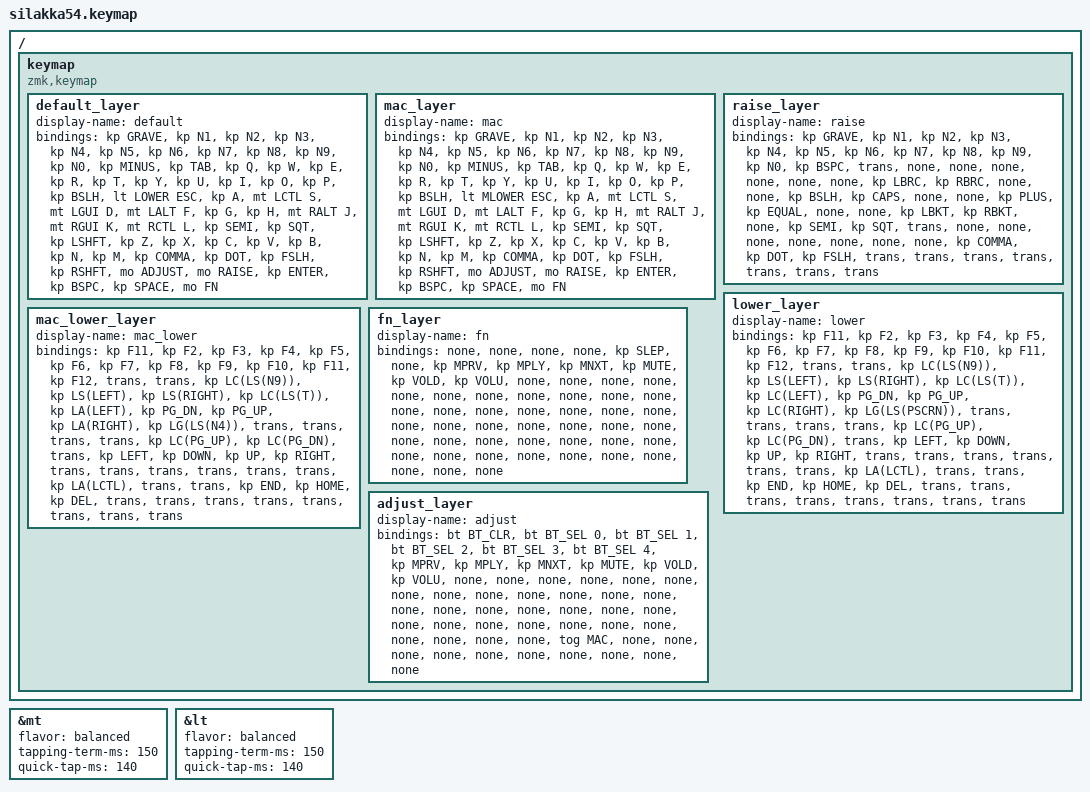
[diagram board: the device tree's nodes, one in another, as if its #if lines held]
/*
 * Copyright (c) 2020 The ZMK Contributors
 *
 * SPDX-License-Identifier: MIT
 */

#include <behaviors.dtsi>
#include <dt-bindings/zmk/keys.h>
#include <dt-bindings/zmk/bt.h>
#include <dt-bindings/zmk/ext_power.h>

#define BASE 0
#define MAC 1
#define RAISE 2
#define LOWER 3
#define MLOWER 4
#define FN 5
#define ADJUST 6
#define SLEP C_SLEEP
#define MPRV C_PREV
#define MPLY C_PP
#define MNXT C_NEXT
#define MUTE C_MUTE
#ifdef VOLD
    #undef VOLD
    #define VOLD C_VOL_DN
#endif
#ifdef VOLU
    #undef VOLU
    #define VOLU C_VOL_UP
#endif


&mt {
    flavor = "balanced";
    tapping-term-ms = <150>;
    quick-tap-ms = <140>;
};

&lt {
    flavor = "balanced";
    tapping-term-ms = <150>;
    quick-tap-ms = <140>;
};

/ {

    keymap {
        compatible = "zmk,keymap";

        default_layer {
            display-name = "default";
// -----------------------------------------------------------------------------------------------------------
// |   `   |  1  |  2  |  3   |  4   |  5   |                   |  6   |  7    |  8    |  9   |   0   |  -   |
// |  TAB  |  Q  |  W  |  E   |  R   |  T   |                   |  Y   |  U    |  I    |  O   |   P   | BSLH |
// |  ESC  |  A  |  S  |  D   |  F   |  G   |                   |  H   |  J    |  K    |  L   |   ;   |  '   |
// | SHIFT |  Z  |  X  |  C   |  V   |  B   |                   |  N   |  M    |  ,    |  .   |   /   | SHFT |
//                      |  ADJUST   | RAISE |  ENTER |           | BSPC  | SPACE |  FN  |
            bindings = <
&kp GRAVE       &kp N1 &kp N2        &kp N3        &kp N4         &kp N5              &kp N6 &kp N7     &kp N8      &kp N9        &kp N0   &kp MINUS
&kp TAB         &kp Q  &kp W         &kp E         &kp R          &kp T               &kp Y  &kp U      &kp I       &kp O         &kp P    &kp BSLH
&lt LOWER ESC   &kp A  &mt LCTL S    &mt LGUI D    &mt LALT F     &kp G               &kp H  &mt RALT J &mt RGUI K  &mt RCTL L    &kp SEMI &kp SQT
&kp LSHFT       &kp Z  &kp X         &kp C         &kp V          &kp B               &kp N  &kp M      &kp COMMA   &kp DOT       &kp FSLH &kp RSHFT
                                            &mo ADJUST   &mo RAISE &kp ENTER        &kp BSPC      &kp SPACE &mo FN
            >;
        };

        mac_layer {
            display-name = "mac";
// -----------------------------------------------------------------------------------------------------------
// |   `   |  1  |  2  |  3   |  4   |  5   |                   |  6   |  7    |  8    |  9   |   0   |  -   |
// |  TAB  |  Q  |  W  |  E   |  R   |  T   |                   |  Y   |  U    |  I    |  O   |   P   | BSLH |
// |  ESC  |  A  |  S  |  D   |  F   |  G   |                   |  H   |  J    |  K    |  L   |   ;   |  '   |
// | SHIFT |  Z  |  X  |  C   |  V   |  B   |                   |  N   |  M    |  ,    |  .   |   /   | SHFT |
//                      |  ADJUST   | RAISE |  ENTER |           | BSPC  | SPACE |  FN  |
            bindings = <
&kp GRAVE       &kp N1 &kp N2        &kp N3        &kp N4         &kp N5              &kp N6 &kp N7     &kp N8      &kp N9        &kp N0   &kp MINUS
&kp TAB         &kp Q  &kp W         &kp E         &kp R          &kp T               &kp Y  &kp U      &kp I       &kp O         &kp P    &kp BSLH
&lt MLOWER ESC  &kp A  &mt LCTL S    &mt LGUI D    &mt LALT F     &kp G               &kp H  &mt RALT J &mt RGUI K  &mt RCTL L    &kp SEMI &kp SQT
&kp LSHFT       &kp Z  &kp X         &kp C         &kp V          &kp B               &kp N  &kp M      &kp COMMA   &kp DOT       &kp FSLH &kp RSHFT
                                            &mo ADJUST   &mo RAISE &kp ENTER        &kp BSPC      &kp SPACE &mo FN
            >;
        };

        raise_layer {
            display-name = "raise";
// ----------------------------------------------------------------------------------------------------------
// |  `   |  1  |  2  |  3   |  4   |  5   |                   |  6   |  7    |  8    |  9   |   0   |  -   |
// | TAB  |     |     |      |      |      |                   |      |  {    |  }    |      |       |  \   |
// | CAPS |     |     |  +   |  =   |      |                   |      |  [    |  ]    |      |   ;   |  '   |
// | SHFT |     |     |      |      |      |                   |      |       |   ,   |   .  |   /   | SHFT |
//                      |  ADJUST   | RAISE |  ENTER |           | BSPC  | SPACE |  FN  |
            bindings = <
&kp GRAVE &kp N1    &kp N2  &kp N3      &kp N4      &kp N5          &kp N6  &kp N7      &kp N8      &kp N9  &kp N0      &kp BSPC
&trans    &none     &none   &none       &none       &none           &none   &kp LBRC    &kp RBRC    &none   &none       &kp BSLH
&kp CAPS  &none     &none   &kp PLUS    &kp EQUAL   &none           &none   &kp LBKT    &kp RBKT    &none   &kp SEMI    &kp SQT
&trans    &none     &none   &none       &none       &none           &none   &none       &kp COMMA   &kp DOT &kp FSLH    &trans
                                 &trans    &trans    &trans       &trans    &trans   &trans
            >;
        };

        lower_layer {
            display-name = "lower";
// -----------------------------------------------------------------------------------------------------------------
// | F1 | F2 |   F3    |   F4    |   F5    |   F6    |          |  F7   |  F8  |  F9  |  F10  |  F11         | F12 |
// |    |    | C(S(9)) | S(<-)   | S(->)   | C(S(T)) |          | C(<-) | PGDN | PGUP | C(->) | G(S(PRSCRN)) |     |
// |    |    |         | C(PGUP) | C(PGDN) |         |          |  <-   |  v   |  ^   |  ->   |              |     |
// |    |    |         |         |  A(CTL) |         |          |       |      |      |       |              |     |
//                      |  ADJUST   | RAISE |  ENTER |           | BSPC  | SPACE |  FN  |
            bindings = <
&kp F11 &kp F2  &kp F3          &kp F4          &kp F5          &kp F6                  &kp F7          &kp F8      &kp F9      &kp F10         &kp F11             &kp F12
&trans  &trans  &kp LC(LS(N9))  &kp LS(LEFT)    &kp LS(RIGHT)   &kp LC(LS(T))           &kp LC(LEFT)    &kp PG_DN   &kp PG_UP   &kp LC(RIGHT)   &kp LG(LS(PSCRN))   &trans
&trans  &trans  &trans          &kp LC(PG_UP)   &kp LC(PG_DN)   &trans                  &kp LEFT        &kp DOWN    &kp UP      &kp RIGHT       &trans              &trans
&trans  &trans  &trans          &trans          &kp LA(LCTL)    &trans                  &trans          &kp END     &kp HOME    &kp DEL         &trans              &trans
                                        &trans       &trans       &trans              &trans    &trans    &trans
            >;
        };

        mac_lower_layer {
            display-name = "mac_lower";
// -----------------------------------------------------------------------------------------------------------------
// | F1 | F2 |   F3    |   F4    |   F5    |   F6    |          |  F7   |  F8  |  F9  |  F10  |  F11         | F12 |
// |    |    | C(S(9)) | S(<-)   | S(->)   | C(S(T)) |          | A(<-) | PGDN | PGUP | A(->) | G(S(PRSCRN)) |     |
// |    |    |         | C(PGUP) | C(PGDN) |         |          |  <-   |  v   |  ^   |  ->   |              |     |
// |    |    |         |         |  A(CTL) |         |          |       |      |      |       |              |     |
//                      |  ADJUST   | RAISE |  ENTER |           | BSPC  | SPACE |  FN  |
            bindings = <
&kp F11 &kp F2  &kp F3          &kp F4          &kp F5          &kp F6                  &kp F7          &kp F8      &kp F9      &kp F10         &kp F11             &kp F12
&trans  &trans  &kp LC(LS(N9))  &kp LS(LEFT)    &kp LS(RIGHT)   &kp LC(LS(T))           &kp LA(LEFT)    &kp PG_DN   &kp PG_UP   &kp LA(RIGHT)   &kp LG(LS(N4))   &trans
&trans  &trans  &trans          &kp LC(PG_UP)   &kp LC(PG_DN)   &trans                  &kp LEFT        &kp DOWN    &kp UP      &kp RIGHT       &trans              &trans
&trans  &trans  &trans          &trans          &kp LA(LCTL)    &trans                  &trans          &kp END     &kp HOME    &kp DEL         &trans              &trans
                                        &trans       &trans       &trans              &trans    &trans    &trans
            >;
        };

        fn_layer {
// -------------------------------------------------------------------------------------------------------------------
// | BTCLR  |  BT1    |  BT2    |   BT3   |   BT4   |   BT5   |         | PREV | PLAY |  NEXT | MUTE | VOLD  | VOLU  |
// |        |         |         |         |         |         |         |      |      |       |      |       |       |
// |        |         |         |         |         |         |         |      |      |       |      |       |       |
// |        |         |         |         |         |         |         |      |      |       |      |       |       |
//                                |         |         |         |     |       |      |       |
            display-name = "fn";
            bindings = <
&none   &none   &none   &none   &kp SLEP    &none           &kp MPRV    &kp MPLY    &kp MNXT    &kp MUTE    &kp VOLD    &kp VOLU
&none   &none   &none   &none   &none       &none           &none       &none       &none       &none       &none       &none
&none   &none   &none   &none   &none       &none           &none       &none       &none       &none       &none       &none
&none   &none   &none   &none   &none       &none           &none       &none       &none       &none       &none       &none
                          &none   &none       &none       &none       &none       &none
            >;
        };

        adjust_layer {
// -------------------------------------------------------------------------------------------------------------------
// | BTCLR  |  BT1    |  BT2    |   BT3   |   BT4   |   BT5   |         | PREV | PLAY |  NEXT | MUTE | VOLD  | VOLU  |
// |        |         |         |         |         |         |         |      |      |       |      |       |       |
// |        |         |         |         |         |         |         |      |      |       |      |       |       |
// |        |         |         |         |         |         |         |      |      |       |      |       |       |
//                                |         |         |         |     |       |      |       |
            display-name = "adjust";
            bindings = <
&bt BT_CLR  &bt BT_SEL 0    &bt BT_SEL 1    &bt BT_SEL 2    &bt BT_SEL 3    &bt BT_SEL 4            &kp MPRV    &kp MPLY    &kp MNXT    &kp MUTE    &kp VOLD    &kp VOLU
&none       &none           &none           &none           &none           &none                   &none       &none       &none       &none       &none       &none
&none       &none           &none           &none           &none           &none                   &none       &none       &none       &none       &none       &none
&none       &none           &none           &none           &none           &none                   &none       &tog MAC    &none       &none       &none       &none
                                              &none           &none           &none                &none       &none       &none
            >;
        };

    };
};
